AUTOSAR XML (schema 00046)
package /ComponentTypes
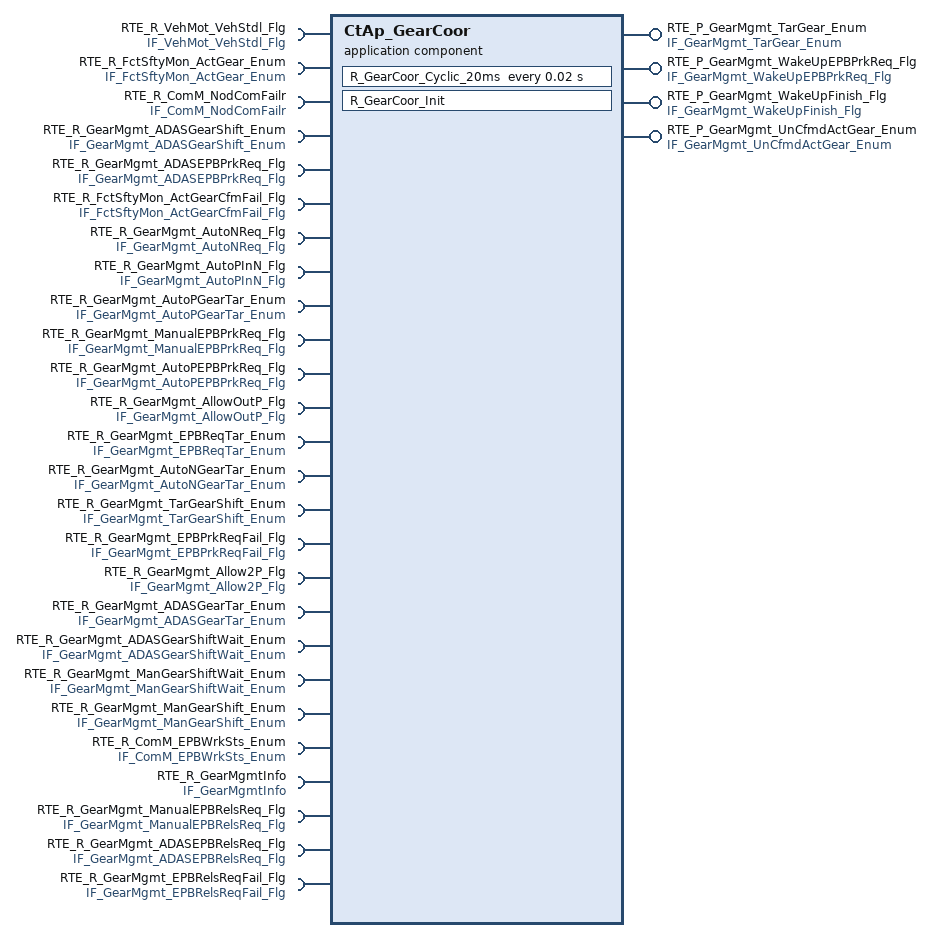
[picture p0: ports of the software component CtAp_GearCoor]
  application sw component type CtAp_GearCoor
    21 x require port:
      RTE_R_VehMot_VehStdl_Flg: nonqueued-receiver-com-spec{data-element=tec_VehMot_VehStdl_Flg, filter=data-filter-type=ALWAYS, init-value=0}, required-interface=IF_VehMot_VehStdl_Flg
      RTE_R_FctSftyMon_ActGear_Enum: nonqueued-receiver-com-spec{data-element=tec_FctSftyMon_ActGear_Enum, filter=data-filter-type=ALWAYS, init-value=0}, required-interface=IF_FctSftyMon_ActGear_Enum
      RTE_R_ComM_NodComFailr: required-interface=IF_ComM_NodComFailr
        required-com-specs:
          data-element=tec_ComM_ACUNodComFailr_Flg, filter=data-filter-type=ALWAYS, init-value=0
          data-element=tec_ComM_SGWNodComFailr_Flg, filter=data-filter-type=ALWAYS, init-value=0
          data-element=tec_ComM_CGWNodComFailr_Flg, filter=data-filter-type=ALWAYS, init-value=0
          data-element=tec_ComM_TCUNodComFailr_Flg, filter=data-filter-type=ALWAYS, init-value=0
          data-element=tec_ComM_BCMNodComFailr_Flg, filter=data-filter-type=ALWAYS, init-value=0
          data-element=tec_ComM_PRNDNodComFailr_Flg, filter=data-filter-type=ALWAYS, init-value=0
          data-element=tec_ComM_IVINodComFailr_Flg, filter=data-filter-type=ALWAYS, init-value=0
          data-element=tec_ComM_DCDCNodComFailr_Flg, filter=data-filter-type=ALWAYS, init-value=0
          data-element=tec_ComM_OBCNodComFailr_Flg, filter=data-filter-type=ALWAYS, init-value=0
          data-element=tec_ComM_CHIBSNodComFailr_Flg, filter=data-filter-type=ALWAYS, init-value=0
          data-element=tec_ComM_MCUNodComFailr_Flg, filter=data-filter-type=ALWAYS, init-value=0
          data-element=tec_ComM_EVCOMNodComFailr_Flg, filter=data-filter-type=ALWAYS, init-value=0
          data-element=tec_ComM_EPTIBSNodComFailr_Flg, filter=data-filter-type=ALWAYS, init-value=0
          data-element=tec_ComM_DCMNodComFailr_Flg, filter=data-filter-type=ALWAYS, init-value=0
          data-element=tec_ComM_BMSNodComFailr_Flg, filter=data-filter-type=ALWAYS, init-value=0
          data-element=tec_ComM_APTCNodComFailr_Flg, filter=data-filter-type=ALWAYS, init-value=0
          data-element=tec_ComM_ADCUNodComFailr_Flg, filter=data-filter-type=ALWAYS, init-value=0
          data-element=tec_ComM_DCMRRNodComFailr_Flg, filter=data-filter-type=ALWAYS, init-value=0
          data-element=tec_ComM_DCMRLNodComFailr_Flg, filter=data-filter-type=ALWAYS, init-value=0
          data-element=tec_ComM_DCMFRNodComFailr_Flg, filter=data-filter-type=ALWAYS, init-value=0
          data-element=tec_ComM_DCMFLNodComFailr_Flg, filter=data-filter-type=ALWAYS, init-value=0
          data-element=tec_ComM_SGWCHNodComFailr_Flg, init-value=0
      RTE_R_GearMgmt_ADASGearShift_Enum: nonqueued-receiver-com-spec{data-element=tec_GearMgmt_ADASGearShift_Enum, filter=data-filter-type=ALWAYS, init-value=0}, required-interface=IF_GearMgmt_ADASGearShift_Enum
      RTE_R_GearMgmt_ADASEPBPrkReq_Flg: nonqueued-receiver-com-spec{data-element=tec_GearMgmt_ADASEPBPrkReq_Flg, filter=data-filter-type=ALWAYS, init-value=0}, required-interface=IF_GearMgmt_ADASEPBPrkReq_Flg
      RTE_R_FctSftyMon_ActGearCfmFail_Flg: nonqueued-receiver-com-spec{data-element=tec_FctSftyMon_ActGearCfmFail_Flg, filter=data-filter-type=ALWAYS, init-value=0}, required-interface=IF_FctSftyMon_ActGearCfmFail_Flg
      RTE_R_GearMgmt_AutoNReq_Flg: nonqueued-receiver-com-spec{data-element=tec_GearMgmt_AutoNReq_Flg, filter=data-filter-type=ALWAYS, init-value=0}, required-interface=IF_GearMgmt_AutoNReq_Flg
      RTE_R_GearMgmt_AutoPInN_Flg: nonqueued-receiver-com-spec{data-element=tec_GearMgmt_AutoPInN_Flg, filter=data-filter-type=ALWAYS, init-value=0}, required-interface=IF_GearMgmt_AutoPInN_Flg
      RTE_R_GearMgmt_AutoPGearTar_Enum: nonqueued-receiver-com-spec{data-element=tec_GearMgmt_AutoPGearTar_Enum, filter=data-filter-type=ALWAYS, init-value=0}, required-interface=IF_GearMgmt_AutoPGearTar_Enum
      RTE_R_GearMgmt_ManualEPBPrkReq_Flg: nonqueued-receiver-com-spec{data-element=tec_GearMgmt_ManualEPBPrkReq_Flg, filter=data-filter-type=ALWAYS, init-value=0}, required-interface=IF_GearMgmt_ManualEPBPrkReq_Flg
      RTE_R_GearMgmt_AutoPEPBPrkReq_Flg: nonqueued-receiver-com-spec{data-element=tec_GearMgmt_AutoPEPBPrkReq_Flg, filter=data-filter-type=ALWAYS, init-value=0}, required-interface=IF_GearMgmt_AutoPEPBPrkReq_Flg
      RTE_R_GearMgmt_AllowOutP_Flg: nonqueued-receiver-com-spec{data-element=tec_GearMgmt_AllowOutP_Flg, filter=data-filter-type=ALWAYS, init-value=0}, required-interface=IF_GearMgmt_AllowOutP_Flg
      RTE_R_GearMgmt_EPBReqTar_Enum: nonqueued-receiver-com-spec{data-element=tec_GearMgmt_EPBReqTar_Enum, filter=data-filter-type=ALWAYS, init-value=0}, required-interface=IF_GearMgmt_EPBReqTar_Enum
      RTE_R_GearMgmt_AutoNGearTar_Enum: nonqueued-receiver-com-spec{data-element=tec_GearMgmt_AutoNGearTar_Enum, filter=data-filter-type=ALWAYS, init-value=0}, required-interface=IF_GearMgmt_AutoNGearTar_Enum
      RTE_R_GearMgmt_TarGearShift_Enum: nonqueued-receiver-com-spec{data-element=tec_GearMgmt_ManualGearTar_Enum, filter=data-filter-type=ALWAYS, init-value=0}, required-interface=IF_GearMgmt_TarGearShift_Enum
      RTE_R_GearMgmt_EPBPrkReqFail_Flg: nonqueued-receiver-com-spec{data-element=tec_GearMgmt_EPBPrkReqFail_Flg, filter=data-filter-type=ALWAYS, init-value=0}, required-interface=IF_GearMgmt_EPBPrkReqFail_Flg
      RTE_R_GearMgmt_Allow2P_Flg: nonqueued-receiver-com-spec{data-element=tec_GearMgmt_Allow2P_Flg, filter=data-filter-type=ALWAYS, init-value=0}, required-interface=IF_GearMgmt_Allow2P_Flg
      RTE_R_GearMgmt_ADASGearTar_Enum: nonqueued-receiver-com-spec{data-element=tec_GearMgmt_ADASGearTar_Enum, filter=data-filter-type=ALWAYS, init-value=0}, required-interface=IF_GearMgmt_ADASGearTar_Enum
      RTE_R_GearMgmt_ADASGearShiftWait_Enum: nonqueued-receiver-com-spec{data-element=tec_GearMgmt_ADASGearShiftWait_Enum, filter=data-filter-type=ALWAYS, init-value=0}, required-interface=IF_GearMgmt_ADASGearShiftWait_Enum
      RTE_R_GearMgmt_ManGearShiftWait_Enum: nonqueued-receiver-com-spec{data-element=tec_GearMgmt_ManGearShiftWait_Enum, filter=data-filter-type=ALWAYS, init-value=0}, required-interface=IF_GearMgmt_ManGearShiftWait_Enum
      RTE_R_GearMgmt_ManGearShift_Enum: nonqueued-receiver-com-spec{data-element=tec_GearMgmt_ManGearShift_Enum, filter=data-filter-type=ALWAYS, init-value=0}, required-interface=IF_GearMgmt_ManGearShift_Enum
    4 x provide port:
      RTE_P_GearMgmt_TarGear_Enum: nonqueued-sender-com-spec{data-element=tec_GearMgmt_TarGear_Enum, init-value=0}, provided-interface=IF_GearMgmt_TarGear_Enum
      RTE_P_GearMgmt_WakeUpEPBPrkReq_Flg: nonqueued-sender-com-spec{data-element=tec_GearMgmt_WakeUpEPBPrkReq_Flg, init-value=0}, provided-interface=IF_GearMgmt_WakeUpEPBPrkReq_Flg
      RTE_P_GearMgmt_WakeUpFinish_Flg: nonqueued-sender-com-spec{data-element=tec_GearMgmt_WakeUpFinish_Flg, init-value=0}, provided-interface=IF_GearMgmt_WakeUpFinish_Flg
      RTE_P_GearMgmt_UnCfmdActGear_Enum: nonqueued-sender-com-spec{data-element=tec_GearMgmt_UnCfmdActGear_Enum, init-value=0}, provided-interface=IF_GearMgmt_UnCfmdActGear_Enum
    5 x require port:
      RTE_R_ComM_EPBWrkSts_Enum: nonqueued-receiver-com-spec{data-element=tec_ComM_EPBWrkSts_Enum, filter=data-filter-type=ALWAYS, init-value=0}, required-interface=IF_ComM_EPBWrkSts_Enum
      RTE_R_GearMgmtInfo: nv-require-com-spec{init-value=fields=[GearMgmt_GearMemInfo_Enum:0, GearMgmt_FillAddress:0], variable=tec_GearMgmtInfo}, required-interface=IF_GearMgmtInfo
      RTE_R_GearMgmt_ManualEPBRelsReq_Flg: nonqueued-receiver-com-spec{data-element=tec_GearMgmt_ManualEPBRelsReq_Flg, filter=data-filter-type=ALWAYS, init-value=0}, required-interface=IF_GearMgmt_ManualEPBRelsReq_Flg
      RTE_R_GearMgmt_ADASEPBRelsReq_Flg: nonqueued-receiver-com-spec{data-element=tec_GearMgmt_ADASEPBRelsReq_Flg, filter=data-filter-type=ALWAYS, init-value=0}, required-interface=IF_GearMgmt_ADASEPBRelsReq_Flg
      RTE_R_GearMgmt_EPBRelsReqFail_Flg: nonqueued-receiver-com-spec{data-element=tec_GearMgmt_EPBRelsReqFail_Flg, filter=data-filter-type=ALWAYS, init-value=0}, required-interface=IF_GearMgmt_EPBRelsReqFail_Flg
    behavior CtAp_GearCoor_InternalBehavior
      timing event TMT_R_GearCoor_Cyclic_20ms: start-on-event=R_GearCoor_Cyclic_20ms, period=0.02
      init event CtAp_GearCoor_InitEvent: start-on-event=R_GearCoor_Init
      runnable R_GearCoor_Cyclic_20ms
        data-receive-point-by-arguments:
          26 x access:
            REC_RTE_R_ComM_NodComFailr_tec_ComM_CHIBSNodComFailr_Flg: accessed-variable=RTE_R_ComM_NodComFailr.tec_ComM_CHIBSNodComFailr_Flg
            REC_RTE_R_FctSftyMon_ActGearCfmFail_Flg_tec_FctSftyMon_ActGearCfmFail_Flg: accessed-variable=RTE_R_FctSftyMon_ActGearCfmFail_Flg.tec_FctSftyMon_ActGearCfmFail_Flg
            REC_RTE_R_FctSftyMon_ActGear_Enum_tec_FctSftyMon_ActGear_Enum: accessed-variable=RTE_R_FctSftyMon_ActGear_Enum.tec_FctSftyMon_ActGear_Enum
            REC_RTE_R_GearMgmt_ADASEPBPrkReq_Flg_tec_GearMgmt_ADASEPBPrkReq_Flg: accessed-variable=RTE_R_GearMgmt_ADASEPBPrkReq_Flg.tec_GearMgmt_ADASEPBPrkReq_Flg
            REC_RTE_R_GearMgmt_ADASGearShiftWait_Enum_tec_GearMgmt_ADASGearShiftWait_Enum: accessed-variable=RTE_R_GearMgmt_ADASGearShiftWait_Enum.tec_GearMgmt_ADASGearShiftWait_Enum
            REC_RTE_R_GearMgmt_ADASGearShift_Enum_tec_GearMgmt_ADASGearShift_Enum: accessed-variable=RTE_R_GearMgmt_ADASGearShift_Enum.tec_GearMgmt_ADASGearShift_Enum
            REC_RTE_R_GearMgmt_ADASGearTar_Enum_tec_GearMgmt_ADASGearTar_Enum: accessed-variable=RTE_R_GearMgmt_ADASGearTar_Enum.tec_GearMgmt_ADASGearTar_Enum
            REC_RTE_R_GearMgmt_Allow2P_Flg_tec_GearMgmt_Allow2P_Flg: accessed-variable=RTE_R_GearMgmt_Allow2P_Flg.tec_GearMgmt_Allow2P_Flg
            REC_RTE_R_GearMgmt_AllowOutP_Flg_tec_GearMgmt_AllowOutP_Flg: accessed-variable=RTE_R_GearMgmt_AllowOutP_Flg.tec_GearMgmt_AllowOutP_Flg
            REC_RTE_R_GearMgmt_AutoNGearTar_Enum_tec_GearMgmt_AutoNGearTar_Enum: accessed-variable=RTE_R_GearMgmt_AutoNGearTar_Enum.tec_GearMgmt_AutoNGearTar_Enum
            REC_RTE_R_GearMgmt_AutoNReq_Flg_tec_GearMgmt_AutoNReq_Flg: accessed-variable=RTE_R_GearMgmt_AutoNReq_Flg.tec_GearMgmt_AutoNReq_Flg
            REC_RTE_R_GearMgmt_AutoPEPBPrkReq_Flg_tec_GearMgmt_AutoPEPBPrkReq_Flg: accessed-variable=RTE_R_GearMgmt_AutoPEPBPrkReq_Flg.tec_GearMgmt_AutoPEPBPrkReq_Flg
            REC_RTE_R_GearMgmt_AutoPGearTar_Enum_tec_GearMgmt_AutoPGearTar_Enum: accessed-variable=RTE_R_GearMgmt_AutoPGearTar_Enum.tec_GearMgmt_AutoPGearTar_Enum
            REC_RTE_R_GearMgmt_AutoPInN_Flg_tec_GearMgmt_AutoPInN_Flg: accessed-variable=RTE_R_GearMgmt_AutoPInN_Flg.tec_GearMgmt_AutoPInN_Flg
            REC_RTE_R_GearMgmt_EPBPrkReqFail_Flg_tec_GearMgmt_EPBPrkReqFail_Flg: accessed-variable=RTE_R_GearMgmt_EPBPrkReqFail_Flg.tec_GearMgmt_EPBPrkReqFail_Flg
            REC_RTE_R_GearMgmt_EPBReqTar_Enum_tec_GearMgmt_EPBReqTar_Enum: accessed-variable=RTE_R_GearMgmt_EPBReqTar_Enum.tec_GearMgmt_EPBReqTar_Enum
            REC_RTE_R_GearMgmt_ManGearShiftWait_Enum_tec_GearMgmt_ManGearShiftWait_Enum: accessed-variable=RTE_R_GearMgmt_ManGearShiftWait_Enum.tec_GearMgmt_ManGearShiftWait_Enum
            REC_RTE_R_GearMgmt_ManGearShift_Enum_tec_GearMgmt_ManGearShift_Enum: accessed-variable=RTE_R_GearMgmt_ManGearShift_Enum.tec_GearMgmt_ManGearShift_Enum
            REC_RTE_R_GearMgmt_ManualEPBPrkReq_Flg_tec_GearMgmt_ManualEPBPrkReq_Flg: accessed-variable=RTE_R_GearMgmt_ManualEPBPrkReq_Flg.tec_GearMgmt_ManualEPBPrkReq_Flg
            REC_RTE_R_GearMgmt_TarGearShift_Enum_tec_GearMgmt_ManualGearTar_Enum: accessed-variable=RTE_R_GearMgmt_TarGearShift_Enum.tec_GearMgmt_ManualGearTar_Enum
            REC_RTE_R_VehMot_VehStdl_Flg_tec_VehMot_VehStdl_Flg: accessed-variable=RTE_R_VehMot_VehStdl_Flg.tec_VehMot_VehStdl_Flg
            REC_RTE_R_GearMgmtInfo_tec_GearMgmtInfo: accessed-variable=RTE_R_GearMgmtInfo.tec_GearMgmtInfo
            SEND_RTE_R_ComM_EPBWrkSts_Enum_tec_ComM_EPBWrkSts_Enum: accessed-variable=RTE_R_ComM_EPBWrkSts_Enum.tec_ComM_EPBWrkSts_Enum
            REC_RTE_R_GearMgmt_ADASEPBRelsReq_Flg_tec_GearMgmt_ADASEPBRelsReq_Flg: accessed-variable=RTE_R_GearMgmt_ADASEPBRelsReq_Flg.tec_GearMgmt_ADASEPBRelsReq_Flg
            REC_RTE_R_GearMgmt_EPBRelsReqFail_Flg_tec_GearMgmt_EPBRelsReqFail_Flg: accessed-variable=RTE_R_GearMgmt_EPBRelsReqFail_Flg.tec_GearMgmt_EPBRelsReqFail_Flg
            REC_RTE_R_GearMgmt_ManualEPBRelsReq_Flg_tec_GearMgmt_ManualEPBRelsReq_Flg: accessed-variable=RTE_R_GearMgmt_ManualEPBRelsReq_Flg.tec_GearMgmt_ManualEPBRelsReq_Flg
        data-send-points:
          4 x access:
            SEND_RTE_P_GearMgmt_TarGear_Enum_tec_GearMgmt_TarGear_Enum: accessed-variable=RTE_P_GearMgmt_TarGear_Enum.tec_GearMgmt_TarGear_Enum
            SEND_RTE_P_GearMgmt_UnCfmdActGear_Enum_tec_GearMgmt_UnCfmdActGear_Enum: accessed-variable=RTE_P_GearMgmt_UnCfmdActGear_Enum.tec_GearMgmt_UnCfmdActGear_Enum
            SEND_RTE_P_GearMgmt_WakeUpEPBPrkReq_Flg_tec_GearMgmt_WakeUpEPBPrkReq_Flg: accessed-variable=RTE_P_GearMgmt_WakeUpEPBPrkReq_Flg.tec_GearMgmt_WakeUpEPBPrkReq_Flg
            SEND_RTE_P_GearMgmt_WakeUpFinish_Flg_tec_GearMgmt_WakeUpFinish_Flg: accessed-variable=RTE_P_GearMgmt_WakeUpFinish_Flg.tec_GearMgmt_WakeUpFinish_Flg
      runnable R_GearCoor_Init
  swc implementation CtAp_GearCoor_Implementation: behavior=CtAp_GearCoor_InternalBehavior
